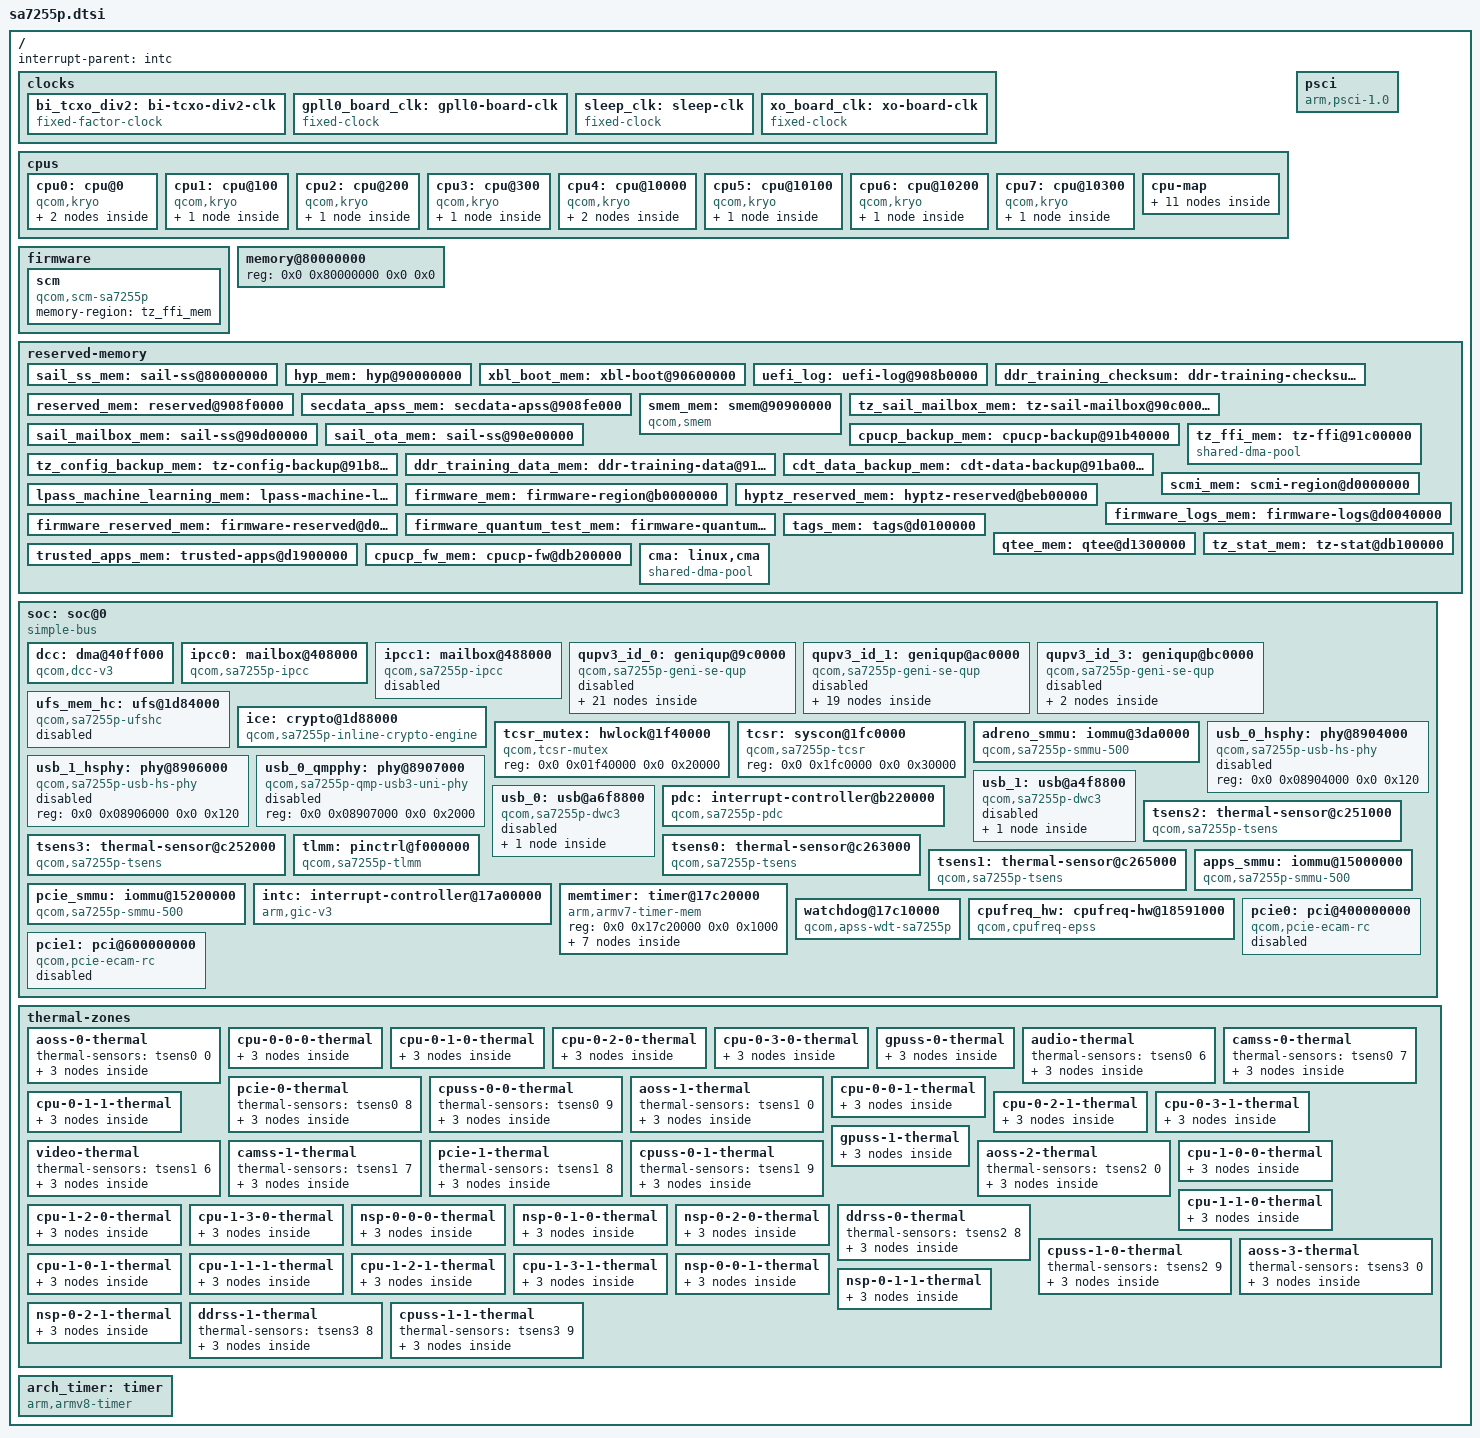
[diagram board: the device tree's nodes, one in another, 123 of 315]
// SPDX-License-Identifier: BSD-3-Clause
/*
 * Copyright (c) 2024 Qualcomm Innovation Center, Inc. All rights reserved.
 */

#include <dt-bindings/interrupt-controller/arm-gic.h>
#include <dt-bindings/mailbox/qcom-ipcc.h>

/ {
	interrupt-parent = <&intc>;

	#address-cells = <2>;
	#size-cells = <2>;

	clocks {
		bi_tcxo_div2: bi-tcxo-div2-clk {
			compatible = "fixed-factor-clock";
			clocks = <&xo_board_clk>;
			clock-mult = <1>;
			clock-div = <2>;
			#clock-cells = <0>;
		};

		gpll0_board_clk: gpll0-board-clk {
			compatible = "fixed-clock";
			#clock-cells = <0>;
		};

		sleep_clk: sleep-clk {
			compatible = "fixed-clock";
			#clock-cells = <0>;
		};

		xo_board_clk: xo-board-clk {
			compatible = "fixed-clock";
			#clock-cells = <0>;
		};
	};

	cpus {
		#address-cells = <2>;
		#size-cells = <0>;

		cpu0: cpu@0 {
			device_type = "cpu";
			compatible = "qcom,kryo";
			reg = <0x0 0x0>;
			enable-method = "psci";
			qcom,freq-domain = <&cpufreq_hw 0>;
			next-level-cache = <&L2_0>;
			L2_0: l2-cache {
			      compatible = "cache";
			      cache-level = <2>;
			      next-level-cache = <&L3_0>;

				L3_0: l3-cache {
				      compatible = "cache";
				      cache-level = <3>;
				};
			};
		};

		cpu1: cpu@100 {
			device_type = "cpu";
			compatible = "qcom,kryo";
			reg = <0x0 0x100>;
			enable-method = "psci";
			qcom,freq-domain = <&cpufreq_hw 0>;
			next-level-cache = <&L2_1>;
			L2_1: l2-cache {
			      compatible = "cache";
			      cache-level = <2>;
			      next-level-cache = <&L3_0>;
			};
		};

		cpu2: cpu@200 {
			device_type = "cpu";
			compatible = "qcom,kryo";
			reg = <0x0 0x200>;
			enable-method = "psci";
			qcom,freq-domain = <&cpufreq_hw 1>;
			next-level-cache = <&L2_2>;
			L2_2: l2-cache {
			      compatible = "cache";
			      cache-level = <2>;
			      next-level-cache = <&L3_0>;
			};
		};

		cpu3: cpu@300 {
			device_type = "cpu";
			compatible = "qcom,kryo";
			reg = <0x0 0x300>;
			enable-method = "psci";
			qcom,freq-domain = <&cpufreq_hw 1>;
			next-level-cache = <&L2_3>;
			L2_3: l2-cache {
			      compatible = "cache";
			      cache-level = <2>;
			      next-level-cache = <&L3_0>;
			};
		};

		cpu4: cpu@10000 {
			device_type = "cpu";
			compatible = "qcom,kryo";
			reg = <0x0 0x10000>;
			enable-method = "psci";
			qcom,freq-domain = <&cpufreq_hw 2>;
			next-level-cache = <&L2_4>;
			L2_4: l2-cache {
			      compatible = "cache";
			      cache-level = <2>;
			      next-level-cache = <&L3_1>;
				L3_1: l3-cache {
				      compatible = "cache";
				      cache-level = <3>;
				};
			};
		};

		cpu5: cpu@10100 {
			device_type = "cpu";
			compatible = "qcom,kryo";
			reg = <0x0 0x10100>;
			enable-method = "psci";
			qcom,freq-domain = <&cpufreq_hw 2>;
			next-level-cache = <&L2_5>;
			L2_5: l2-cache {
			      compatible = "cache";
			      cache-level = <2>;
			      next-level-cache = <&L3_1>;
			};
		};

		cpu6: cpu@10200 {
			device_type = "cpu";
			compatible = "qcom,kryo";
			reg = <0x0 0x10200>;
			enable-method = "psci";
			qcom,freq-domain = <&cpufreq_hw 2>;
			next-level-cache = <&L2_6>;
			L2_6: l2-cache {
			      compatible = "cache";
			      cache-level = <2>;
			      next-level-cache = <&L3_1>;
			};
		};

		cpu7: cpu@10300 {
			device_type = "cpu";
			compatible = "qcom,kryo";
			reg = <0x0 0x10300>;
			enable-method = "psci";
			qcom,freq-domain = <&cpufreq_hw 2>;
			next-level-cache = <&L2_7>;
			L2_7: l2-cache {
			      compatible = "cache";
			      cache-level = <2>;
			      next-level-cache = <&L3_1>;
			};
		};

		cpu-map {
			cluster0 {
				core0 {
					cpu = <&cpu0>;
				};

				core1 {
					cpu = <&cpu1>;
				};
			};

			cluster1 {
				core0 {
					cpu = <&cpu2>;
				};

				core1 {
					cpu = <&cpu3>;
				};
			};

			cluster2 {
				core0 {
					cpu = <&cpu4>;
				};

				core1 {
					cpu = <&cpu5>;
				};

				core2 {
					cpu = <&cpu6>;
				};

				core3 {
					cpu = <&cpu7>;
				};
			};
		};
	};

	firmware: firmware {
		scm {
			compatible = "qcom,scm-sa7255p", "qcom,scm";
			memory-region = <&tz_ffi_mem>;
		};
	};

	memory@80000000 {
		device_type = "memory";
		reg = <0x0 0x80000000 0x0 0x0>;
	};

	psci {
		compatible = "arm,psci-1.0";
		method = "smc";
		mode-bootloader = <0x10001 0x2>;
		mode-edl = <0 0x1>;
	};

	reserved-memory {
		#address-cells = <2>;
		#size-cells = <2>;
		ranges;

		sail_ss_mem: sail-ss@80000000 {
			reg = <0x0 0x80000000 0x0 0x10000000>;
			no-map;
		};

		hyp_mem: hyp@90000000 {
			reg = <0x0 0x90000000 0x0 0x600000>;
			no-map;
		};

		xbl_boot_mem: xbl-boot@90600000 {
			reg = <0x0 0x90600000 0x0 0x200000>;
			no-map;
		};

		uefi_log: uefi-log@908b0000 {
			reg = <0x0 0x908b0000 0x0 0x10000>;
			no-map;
		};

		ddr_training_checksum: ddr-training-checksum@908c0000 {
			reg = <0x0 0x908c0000 0x0 0x1000>;
			no-map;
		};

		reserved_mem: reserved@908f0000 {
			reg = <0x0 0x908f0000 0x0 0xe000>;
			no-map;
		};

		secdata_apss_mem: secdata-apss@908fe000 {
			reg = <0x0 0x908fe000 0x0 0x2000>;
			no-map;
		};

		smem_mem: smem@90900000 {
			compatible = "qcom,smem";
			reg = <0x0 0x90900000 0x0 0x200000>;
			no-map;
			hwlocks = <&tcsr_mutex 3>;
		};

		tz_sail_mailbox_mem: tz-sail-mailbox@90c00000 {
			reg = <0x0 0x90c00000 0x0 0x100000>;
			no-map;
		};

		sail_mailbox_mem: sail-ss@90d00000 {
			reg = <0x0 0x90d00000 0x0 0x100000>;
			no-map;
		};

		sail_ota_mem: sail-ss@90e00000 {
			reg = <0x0 0x90e00000 0x0 0x300000>;
			no-map;
		};

		cpucp_backup_mem: cpucp-backup@91b40000 {
			reg = <0x0 0x91b40000 0x0 0x40000>;
			no-map;
		};

		tz_config_backup_mem: tz-config-backup@91b80000 {
			reg = <0x0 0x91b80000 0x0 0x10000>;
			no-map;
		};

		ddr_training_data_mem: ddr-training-data@91b90000 {
			reg = <0x0 0x91b90000 0x0 0x10000>;
			no-map;
		};

		cdt_data_backup_mem: cdt-data-backup@91ba0000 {
			reg = <0x0 0x91ba0000 0x0 0x1000>;
			no-map;
		};

		tz_ffi_mem: tz-ffi@91c00000 {
			compatible = "shared-dma-pool";
			reg = <0x0 0x91c00000 0x0 0x1400000>;
			no-map;
		};

		lpass_machine_learning_mem: lpass-machine-learning@93b00000 {
			reg = <0x0 0x93b00000 0x0 0xf00000>;
			no-map;
		};

		firmware_mem: firmware-region@b0000000 {
			reg = <0x0 0xb0000000 0x0 0x800000>;
			no-map;
		};

		hyptz_reserved_mem: hyptz-reserved@beb00000 {
			reg = <0x0 0xbeb00000 0x0 0x11500000>;
			no-map;
		};

		scmi_mem: scmi-region@d0000000 {
			reg = <0x0 0xd0000000 0x0 0x40000>;
			no-map;
		};

		firmware_logs_mem: firmware-logs@d0040000 {
			reg = <0x0 0xd0040000 0x0 0x10000>;
			no-map;
		};

		firmware_reserved_mem: firmware-reserved@d0054000 {
			reg = <0x0 0xd0054000 0x0 0x9c000>;
			no-map;
		};

		firmware_quantum_test_mem: firmware-quantum-test@d00f0000 {
			reg = <0x0 0xd00f0000 0x0 0x10000>;
			no-map;
		};

		tags_mem: tags@d0100000 {
			reg = <0x0 0xd0100000 0x0 0x1200000>;
			no-map;
		};

		qtee_mem: qtee@d1300000 {
			reg = <0x0 0xd1300000 0x0 0x500000>;
			no-map;
		};

		trusted_apps_mem: trusted-apps@d1900000 {
			reg = <0x0 0xd1900000 0x0 0x3800000>;
			no-map;
		};

		tz_stat_mem: tz-stat@db100000 {
			reg = <0x0 0xdb100000 0x0 0x100000>;
			no-map;
		};

		cpucp_fw_mem: cpucp-fw@db200000 {
			reg = <0x0 0xdb200000 0x0 0x100000>;
			no-map;
		};

		cma: linux,cma {
			compatible = "shared-dma-pool";
			alloc-ranges = <0x0 0x00000000 0x0 0xdfffffff>;
			reusable;
			alignment = <0x0 0x400000>;
			size = <0x0 0x2000000>;
			linux,cma-default;
		};
	};

	soc: soc@0 {
		compatible = "simple-bus";
		#address-cells = <2>;
		#size-cells = <2>;
		ranges = <0 0 0 0 0x10 0>;

		dcc: dma@40ff000 {
			compatible = "qcom,dcc-v3", "qcom,dcc";
			reg = <0x0 0x040ff000 0x0 0x1000>,
			      <0x0 0x040b8800 0x0 0x6000>;
			qcom,dcc-offset = <0x38800>;
		};

		ipcc0: mailbox@408000 {
			compatible = "qcom,sa7255p-ipcc", "qcom,ipcc";
			reg = <0x0 0x408000 0x0 0x1000>;
			interrupts = <GIC_SPI 229 IRQ_TYPE_LEVEL_HIGH>;
			interrupt-controller;
			#interrupt-cells = <3>;
			#mbox-cells = <2>;
		};

		ipcc1: mailbox@488000 {
			compatible = "qcom,sa7255p-ipcc", "qcom,ipcc";
			reg = <0x0 0x488000 0x0 0x1000>;
			interrupts = <GIC_SPI 231 IRQ_TYPE_LEVEL_HIGH>;
			interrupt-controller;
			#interrupt-cells = <3>;
			#mbox-cells = <2>;
			status = "disabled";
		};

		qupv3_id_0: geniqup@9c0000 {
			compatible = "qcom,sa7255p-geni-se-qup";
			reg = <0x0 0x9c0000 0x0 0x2000>;
			#address-cells = <2>;
			#size-cells = <2>;
			ranges;
			iommus = <&apps_smmu 0x403 0x0>;
			status = "disabled";

			i2c0: i2c@980000 {
				compatible = "qcom,sa7255p-geni-i2c";
				reg = <0x0 0x980000 0x0 0x4000>;
				#address-cells = <1>;
				#size-cells = <0>;
				interrupts = <GIC_SPI 550 IRQ_TYPE_LEVEL_HIGH>;
				status = "disabled";
			};

			spi0: spi@980000 {
				compatible = "qcom,sa7255p-geni-spi";
				reg = <0x0 0x980000 0x0 0x4000>;
				#address-cells = <1>;
				#size-cells = <0>;
				interrupts = <GIC_SPI 550 IRQ_TYPE_LEVEL_HIGH>;
				status = "disabled";
			};

			uart0: serial@980000 {
				compatible = "qcom,sa7255p-geni-uart";
				reg = <0x0 0x980000 0x0 0x4000>;
				interrupts = <GIC_SPI 550 IRQ_TYPE_LEVEL_HIGH>;
				status = "disabled";
			};

			i2c1: i2c@984000 {
				compatible = "qcom,sa7255p-geni-i2c";
				reg = <0x0 0x984000 0x0 0x4000>;
				#address-cells = <1>;
				#size-cells = <0>;
				interrupts = <GIC_SPI 551 IRQ_TYPE_LEVEL_HIGH>;
				status = "disabled";
			};

			spi1: spi@984000 {
				compatible = "qcom,sa7255p-geni-spi";
				reg = <0x0 0x984000 0x0 0x4000>;
				#address-cells = <1>;
				#size-cells = <0>;
				interrupts = <GIC_SPI 551 IRQ_TYPE_LEVEL_HIGH>;
				status = "disabled";
			};

			uart1: serial@984000 {
				compatible = "qcom,sa7255p-geni-uart";
				reg = <0x0 0x984000 0x0 0x4000>;
				interrupts = <GIC_SPI 551 IRQ_TYPE_LEVEL_HIGH>;
				status = "disabled";
			};

			i2c2: i2c@988000 {
				compatible = "qcom,sa7255p-geni-i2c";
				reg = <0x0 0x988000 0x0 0x4000>;
				#address-cells = <1>;
				#size-cells = <0>;
				interrupts = <GIC_SPI 529 IRQ_TYPE_LEVEL_HIGH>;
				status = "disabled";
			};

			spi2: spi@988000 {
				compatible = "qcom,sa7255p-geni-spi";
				reg = <0x0 0x988000 0x0 0x4000>;
				#address-cells = <1>;
				#size-cells = <0>;
				interrupts = <GIC_SPI 529 IRQ_TYPE_LEVEL_HIGH>;
				status = "disabled";
			};

			uart2: serial@988000 {
				compatible = "qcom,sa7255p-geni-uart";
				reg = <0x0 0x988000 0x0 0x4000>;
				interrupts = <GIC_SPI 529 IRQ_TYPE_LEVEL_HIGH>;
				status = "disabled";
			};

			i2c3: i2c@98c000 {
				compatible = "qcom,sa7255p-geni-i2c";
				reg = <0x0 0x98c000 0x0 0x4000>;
				#address-cells = <1>;
				#size-cells = <0>;
				interrupts = <GIC_SPI 530 IRQ_TYPE_LEVEL_HIGH>;
				status = "disabled";
			};

			spi3: spi@98c000 {
				compatible = "qcom,sa7255p-geni-spi";
				reg = <0x0 0x98c000 0x0 0x4000>;
				#address-cells = <1>;
				#size-cells = <0>;
				interrupts = <GIC_SPI 530 IRQ_TYPE_LEVEL_HIGH>;
				status = "disabled";
			};

			uart3: serial@98c000 {
				compatible = "qcom,sa7255p-geni-uart";
				reg = <0x0 0x98c000 0x0 0x4000>;
				interrupts = <GIC_SPI 530 IRQ_TYPE_LEVEL_HIGH>;
				status = "disabled";
			};

			i2c4: i2c@990000 {
				compatible = "qcom,sa7255p-geni-i2c";
				reg = <0x0 0x990000 0x0 0x4000>;
				#address-cells = <1>;
				#size-cells = <0>;
				interrupts = <GIC_SPI 531 IRQ_TYPE_LEVEL_HIGH>;
				status = "disabled";
			};

			spi4: spi@990000 {
				compatible = "qcom,sa7255p-geni-spi";
				reg = <0x0 0x990000 0x0 0x4000>;
				#address-cells = <1>;
				#size-cells = <0>;
				interrupts = <GIC_SPI 531 IRQ_TYPE_LEVEL_HIGH>;
				status = "disabled";
			};

			uart4: serial@990000 {
				compatible = "qcom,sa7255p-geni-uart";
				reg = <0x0 0x990000 0x0 0x4000>;
				interrupts = <GIC_SPI 531 IRQ_TYPE_LEVEL_HIGH>;
				status = "disabled";
			};

			i2c5: i2c@994000 {
				compatible = "qcom,sa7255p-geni-i2c";
				reg = <0x0 0x994000 0x0 0x4000>;
				#address-cells = <1>;
				#size-cells = <0>;
				interrupts = <GIC_SPI 535 IRQ_TYPE_LEVEL_HIGH>;
				status = "disabled";
			};

			spi5: spi@994000 {
				compatible = "qcom,sa7255p-geni-spi";
				reg = <0x0 0x994000 0x0 0x4000>;
				#address-cells = <1>;
				#size-cells = <0>;
				interrupts = <GIC_SPI 535 IRQ_TYPE_LEVEL_HIGH>;
				status = "disabled";
			};

			uart5: serial@994000 {
				compatible = "qcom,sa7255p-geni-uart";
				reg = <0x0 0x994000 0x0 0x4000>;
				interrupts = <GIC_SPI 535 IRQ_TYPE_LEVEL_HIGH>;
				status = "disabled";
			};

			i2c6: i2c@998000 {
				compatible = "qcom,sa7255p-geni-i2c";
				reg = <0x0 0x998000 0x0 0x4000>;
				#address-cells = <1>;
				#size-cells = <0>;
				interrupts = <GIC_SPI 536 IRQ_TYPE_LEVEL_HIGH>;
				status = "disabled";
			};

			spi6: spi@998000 {
				compatible = "qcom,sa7255p-geni-spi";
				reg = <0x0 0x998000 0x0 0x4000>;
				#address-cells = <1>;
				#size-cells = <0>;
				interrupts = <GIC_SPI 536 IRQ_TYPE_LEVEL_HIGH>;
				status = "disabled";
			};

			uart7: serial@99c000 {
				compatible = "qcom,sa7255p-geni-debug-uart";
				reg = <0x0 0x0099c000 0x0 0x4000>;
				interrupts = <GIC_SPI 126 IRQ_TYPE_LEVEL_HIGH>;
				status = "disabled";
			};

		};

		qupv3_id_1: geniqup@ac0000 {
			compatible = "qcom,sa7255p-geni-se-qup";
			reg = <0x0 0x00ac0000 0x0 0x2000>;
			#address-cells = <2>;
			#size-cells = <2>;
			ranges;
			iommus = <&apps_smmu 0x443 0x0>;
			status = "disabled";

			i2c8: i2c@a80000 {
				compatible = "qcom,sa7255p-geni-i2c";
				reg = <0x0 0xa80000 0x0 0x4000>;
				#address-cells = <1>;
				#size-cells = <0>;
				interrupts = <GIC_SPI 353 IRQ_TYPE_LEVEL_HIGH>;
				status = "disabled";
			};

			spi8: spi@a80000 {
				compatible = "qcom,sa7255p-geni-spi";
				reg = <0x0 0xa80000 0x0 0x4000>;
				#address-cells = <1>;
				#size-cells = <0>;
				interrupts = <GIC_SPI 353 IRQ_TYPE_LEVEL_HIGH>;
				status = "disabled";
			};

			i2c9: i2c@a84000 {
				compatible = "qcom,sa7255p-geni-i2c";
				reg = <0x0 0xa84000 0x0 0x4000>;
				#address-cells = <1>;
				#size-cells = <0>;
				interrupts = <GIC_SPI 354 IRQ_TYPE_LEVEL_HIGH>;
				status = "disabled";
			};

			spi9: spi@a84000 {
				compatible = "qcom,sa7255p-geni-spi";
				reg = <0x0 0xa84000 0x0 0x4000>;
				#address-cells = <1>;
				#size-cells = <0>;
				interrupts = <GIC_SPI 354 IRQ_TYPE_LEVEL_HIGH>;
				status = "disabled";
			};

			uart9: serial@a84000 {
				compatible = "qcom,sa7255p-geni-uart";
				reg = <0x0 0x00a84000 0x0 0x4000>;
				interrupts = <GIC_SPI 354 IRQ_TYPE_LEVEL_HIGH>;
				status = "disabled";
			};

			i2c10: i2c@a88000 {
				compatible = "qcom,sa7255p-geni-i2c";
				reg = <0x0 0xa88000 0x0 0x4000>;
				#address-cells = <1>;
				#size-cells = <0>;
				interrupts = <GIC_SPI 355 IRQ_TYPE_LEVEL_HIGH>;
				status = "disabled";
			};

			spi10: spi@a88000 {
				compatible = "qcom,sa7255p-geni-spi";
				reg = <0x0 0xa88000 0x0 0x4000>;
				#address-cells = <1>;
				#size-cells = <0>;
				interrupts = <GIC_SPI 355 IRQ_TYPE_LEVEL_HIGH>;
				status = "disabled";
			};

			uart10: serial@a88000 {
				compatible = "qcom,sa7255p-geni-uart";
				reg = <0x0 0xa88000 0x0 0x4000>;
				interrupts = <GIC_SPI 355 IRQ_TYPE_LEVEL_HIGH>;
				status = "disabled";
			};

			i2c11: i2c@a8c000 {
				compatible = "qcom,sa7255p-geni-i2c";
				reg = <0x0 0xa8c000 0x0 0x4000>;
				#address-cells = <1>;
				#size-cells = <0>;
				interrupts = <GIC_SPI 356 IRQ_TYPE_LEVEL_HIGH>;
				status = "disabled";
			};

			spi11: spi@a8c000 {
				compatible = "qcom,sa7255p-geni-spi";
				reg = <0x0 0xa8c000 0x0 0x4000>;
				#address-cells = <1>;
				#size-cells = <0>;
				interrupts = <GIC_SPI 356 IRQ_TYPE_LEVEL_HIGH>;
				status = "disabled";
			};

			uart11: serial@a8c000 {
				compatible = "qcom,sa7255p-geni-debug-uart";
				reg = <0x0 0x00a8c000 0x0 0x4000>;
				interrupts = <GIC_SPI 356 IRQ_TYPE_LEVEL_HIGH>;
				status = "disabled";
			};

			i2c12: i2c@a90000 {
				compatible = "qcom,sa7255p-geni-i2c";
				reg = <0x0 0xa90000 0x0 0x4000>;
				#address-cells = <1>;
				#size-cells = <0>;
				interrupts = <GIC_SPI 357 IRQ_TYPE_LEVEL_HIGH>;
				status = "disabled";
			};

			spi12: spi@a90000 {
				compatible = "qcom,sa7255p-geni-spi";
				reg = <0x0 0xa90000 0x0 0x4000>;
				#address-cells = <1>;
				#size-cells = <0>;
				interrupts = <GIC_SPI 357 IRQ_TYPE_LEVEL_HIGH>;
				status = "disabled";
			};

			uart12: serial@a90000 {
				compatible = "qcom,sa7255p-geni-uart";
				reg = <0x0 0x00a90000 0x0 0x4000>;
				interrupts = <GIC_SPI 357 IRQ_TYPE_LEVEL_HIGH>;
				status = "disabled";
			};

			i2c13: i2c@a94000 {
				compatible = "qcom,sa7255p-geni-i2c";
				reg = <0x0 0xa94000 0x0 0x4000>;
				#address-cells = <1>;
				#size-cells = <0>;
				interrupts = <GIC_SPI 358 IRQ_TYPE_LEVEL_HIGH>;
				status = "disabled";
			};

			spi13: spi@a94000 {
				compatible = "qcom,sa7255p-geni-spi";
				reg = <0x0 0xa94000 0x0 0x4000>;
				#address-cells = <1>;
				#size-cells = <0>;
				interrupts = <GIC_SPI 358 IRQ_TYPE_LEVEL_HIGH>;
				status = "disabled";
			};

			uart13: serial@a94000 {
				compatible = "qcom,sa7255p-geni-uart";
				reg = <0x0 0x00a94000 0x0 0x4000>;
				interrupts = <GIC_SPI 358 IRQ_TYPE_LEVEL_HIGH>;
				status = "disabled";
			};

			i2c14: i2c@a98000 {
				compatible = "qcom,sa7255p-geni-i2c";
				reg = <0x0 0xa98000 0x0 0x4000>;
				#address-cells = <1>;
				#size-cells = <0>;
				interrupts = <GIC_SPI 835 IRQ_TYPE_LEVEL_HIGH>;
				status = "disabled";
			};

			i2c15: i2c@a9c000 {
				compatible = "qcom,sa7255p-geni-i2c";
				reg = <0x0 0xa9c000 0x0 0x4000>;
				#address-cells = <1>;
				#size-cells = <0>;
				interrupts = <GIC_SPI 125 IRQ_TYPE_LEVEL_HIGH>;
				status = "disabled";
			};
		};

		qupv3_id_3: geniqup@bc0000 {
			compatible = "qcom,sa7255p-geni-se-qup";
			reg = <0x0 0xbc0000 0x0 0x2000>;
			#address-cells = <2>;
			#size-cells = <2>;
			ranges;
			iommus = <&apps_smmu 0x43 0x0>;
			status = "disabled";

			i2c16: i2c@b80000 {
				compatible = "qcom,sa7255p-geni-i2c";
				reg = <0x0 0xb80000 0x0 0x4000>;
				#address-cells = <1>;
				#size-cells = <0>;
				interrupts = <GIC_SPI 830 IRQ_TYPE_LEVEL_HIGH>;
				status = "disabled";
			};

			spi16: spi@b80000 {
				compatible = "qcom,sa7255p-geni-spi";
				reg = <0x0 0xb80000 0x0 0x4000>;
				#address-cells = <1>;
				#size-cells = <0>;
				interrupts = <GIC_SPI 830 IRQ_TYPE_LEVEL_HIGH>;
				status = "disabled";
			};
		};

		ufs_mem_hc: ufs@1d84000 {
			compatible = "qcom,sa7255p-ufshc", "qcom,ufshc", "jedec,ufs-2.0";
			reg = <0x0 0x01d84000 0x0 0x3000>;
			interrupts = <GIC_SPI 265 IRQ_TYPE_LEVEL_HIGH>;
			lanes-per-direction = <2>;
			iommus = <&apps_smmu 0x100 0x0>;
			dma-coherent;
			qcom,ice = <&ice>;
			status = "disabled";
		};

		ice: crypto@1d88000 {
			compatible = "qcom,sa7255p-inline-crypto-engine",
				     "qcom,inline-crypto-engine";
			reg = <0x0 0x01d88000 0x0 0x10000>;
			qcom,ice-use-hwkm;
			qcom,ice-skip-clk;
		};

		tcsr_mutex: hwlock@1f40000 {
			compatible = "qcom,tcsr-mutex";
			reg = <0x0 0x01f40000 0x0 0x20000>;
			#hwlock-cells = <1>;
		};

		tcsr: syscon@1fc0000 {
			compatible = "qcom,sa7255p-tcsr", "syscon";
			reg = <0x0 0x1fc0000 0x0 0x30000>;
		};

		adreno_smmu: iommu@3da0000 {
			compatible = "qcom,sa7255p-smmu-500", "qcom,adreno-smmu",
				     "qcom,smmu-500", "arm,mmu-500";
			reg = <0x0 0x03da0000 0x0 0x20000>;
			#iommu-cells = <2>;
			#global-interrupts = <2>;
			dma-coherent;

			interrupts = <GIC_SPI 672 IRQ_TYPE_LEVEL_HIGH>,
				     <GIC_SPI 673 IRQ_TYPE_LEVEL_HIGH>,
				     <GIC_SPI 678 IRQ_TYPE_LEVEL_HIGH>,
				     <GIC_SPI 679 IRQ_TYPE_LEVEL_HIGH>,
				     <GIC_SPI 680 IRQ_TYPE_LEVEL_HIGH>,
				     <GIC_SPI 681 IRQ_TYPE_LEVEL_HIGH>,
				     <GIC_SPI 682 IRQ_TYPE_LEVEL_HIGH>,
				     <GIC_SPI 683 IRQ_TYPE_LEVEL_HIGH>,
				     <GIC_SPI 684 IRQ_TYPE_LEVEL_HIGH>,
				     <GIC_SPI 685 IRQ_TYPE_LEVEL_HIGH>,
				     <GIC_SPI 686 IRQ_TYPE_LEVEL_HIGH>,
				     <GIC_SPI 687 IRQ_TYPE_LEVEL_HIGH>;
		};

		usb_0_hsphy: phy@8904000 {
			compatible = "qcom,sa7255p-usb-hs-phy",
				     "qcom,usb-snps-hs-5nm-phy";
			reg = <0x0 0x08904000 0x0 0x120>;
			#phy-cells = <0>;

			status = "disabled";
		};

		usb_1_hsphy: phy@8906000 {
			compatible = "qcom,sa7255p-usb-hs-phy",
				     "qcom,usb-snps-hs-5nm-phy";
			reg = <0x0 0x08906000 0x0 0x120>;
			#phy-cells = <0>;

			status = "disabled";
		};

		usb_0_qmpphy: phy@8907000 {
			compatible = "qcom,sa7255p-qmp-usb3-uni-phy";
			reg = <0x0 0x08907000 0x0 0x2000>;

			#phy-cells = <0>;

			status = "disabled";
		};

		usb_1: usb@a4f8800 {
			compatible = "qcom,sa7255p-dwc3", "qcom,dwc3";
			reg = <0x0 0x0a4f8800 0x0 0x400>;
			#address-cells = <2>;
			#size-cells = <2>;
			ranges;

			interrupts-extended = <&intc GIC_SPI 444 IRQ_TYPE_LEVEL_HIGH>,
					      <&pdc 10 IRQ_TYPE_EDGE_BOTH>,
					      <&pdc 9 IRQ_TYPE_EDGE_BOTH>;
			interrupt-names = "pwr_event",
					  "dp_hs_phy_irq",
					  "dm_hs_phy_irq";

			status = "disabled";

			usb_1_dwc3: usb@a400000 {
				compatible = "snps,dwc3";
				reg = <0x0 0x0a400000 0x0 0xe000>;
				interrupts = <GIC_SPI 442 IRQ_TYPE_LEVEL_HIGH>;
				iommus = <&apps_smmu 0x020 0x0>;
				phys = <&usb_1_hsphy>;
				phy-names = "usb2-phy";
			};
		};

		usb_0: usb@a6f8800 {
			compatible = "qcom,sa7255p-dwc3", "qcom,dwc3";
			reg = <0x0 0x0a6f8800 0x0 0x400>;
			#address-cells = <2>;
			#size-cells = <2>;
			ranges;

			interrupts-extended = <&intc GIC_SPI 287 IRQ_TYPE_LEVEL_HIGH>,
					      <&pdc 14 IRQ_TYPE_EDGE_BOTH>,
					      <&pdc 15 IRQ_TYPE_EDGE_BOTH>,
					      <&pdc 12 IRQ_TYPE_LEVEL_HIGH>;
			interrupt-names = "pwr_event",
					  "dp_hs_phy_irq",
					  "dm_hs_phy_irq",
					  "ss_phy_irq";

			status = "disabled";

			usb_0_dwc3: usb@a600000 {
				compatible = "snps,dwc3";
				reg = <0x0 0x0a600000 0x0 0xe000>;
				interrupts = <GIC_SPI 292 IRQ_TYPE_LEVEL_HIGH>;
				iommus = <&apps_smmu 0x080 0x0>;
				phys = <&usb_0_hsphy>, <&usb_0_qmpphy>;
				phy-names = "usb2-phy", "usb3-phy";
			};
		};

		pdc: interrupt-controller@b220000 {
			compatible = "qcom,sa7255p-pdc", "qcom,pdc";
			reg = <0x0 0x0b220000 0x0 0x30000>,
			      <0x0 0x17c000f0 0x0 0x64>;
			qcom,pdc-ranges = <0 480 40>,
					  <40 140 14>,
					  <54 263 1>,
					  <55 306 4>,
					  <59 312 3>,
					  <62 374 2>,
					  <64 434 2>,
					  <66 438 2>,
					  <70 520 1>,
					  <73 523 1>,
					  <118 568 6>,
					  <124 609 3>,
					  <159 638 1>,
					  <160 720 3>,
					  <169 728 30>,
					  <199 416 2>,
					  <201 449 1>,
					  <202 89 1>,
					  <203 451 1>,
					  <204 462 1>,
					  <205 264 1>,
					  <206 579 1>,
					  <207 653 1>,
					  <208 656 1>,
					  <209 659 1>,
					  <210 122 1>,
					  <211 699 1>,
					  <212 705 1>,
					  <213 450 1>,
					  <214 643 2>,
					  <216 646 5>,
					  <221 390 5>,
					  <226 700 2>,
					  <228 440 1>,
					  <229 663 1>,
					  <230 524 2>,
					  <232 612 3>,
					  <235 723 5>;
			#interrupt-cells = <2>;
			interrupt-parent = <&intc>;
			interrupt-controller;
		};

		tsens2: thermal-sensor@c251000 {
			compatible = "qcom,sa7255p-tsens", "qcom,tsens-v2";
			reg = <0x0 0x0c251000 0x0 0x1ff>,
			      <0x0 0x0c224000 0x0 0x8>;
			interrupts = <GIC_SPI 572 IRQ_TYPE_LEVEL_HIGH>,
				     <GIC_SPI 609 IRQ_TYPE_LEVEL_HIGH>;
			#qcom,sensors = <10>;
			interrupt-names = "uplow", "critical";
			#thermal-sensor-cells = <1>;
		};

		tsens3: thermal-sensor@c252000 {
			compatible = "qcom,sa7255p-tsens", "qcom,tsens-v2";
			reg = <0x0 0x0c252000 0x0 0x1ff>,
			      <0x0 0x0c225000 0x0 0x8>;
			interrupts = <GIC_SPI 573 IRQ_TYPE_LEVEL_HIGH>,
				     <GIC_SPI 610 IRQ_TYPE_LEVEL_HIGH>;
			#qcom,sensors = <10>;
			interrupt-names = "uplow", "critical";
			#thermal-sensor-cells = <1>;
		};

		tsens0: thermal-sensor@c263000 {
			compatible = "qcom,sa7255p-tsens", "qcom,tsens-v2";
			reg = <0x0 0x0c263000 0x0 0x1ff>,
			      <0x0 0x0c222000 0x0 0x8>;
			interrupts = <GIC_SPI 506 IRQ_TYPE_LEVEL_HIGH>,
				     <GIC_SPI 508 IRQ_TYPE_LEVEL_HIGH>;
			#qcom,sensors = <10>;
			interrupt-names = "uplow", "critical";
			#thermal-sensor-cells = <1>;
		};

		tsens1: thermal-sensor@c265000 {
			compatible = "qcom,sa7255p-tsens", "qcom,tsens-v2";
			reg = <0x0 0x0c265000 0x0 0x1ff>,
			      <0x0 0x0c223000 0x0 0x8>;
			interrupts = <GIC_SPI 507 IRQ_TYPE_LEVEL_HIGH>,
				     <GIC_SPI 509 IRQ_TYPE_LEVEL_HIGH>;
			#qcom,sensors = <10>;
			interrupt-names = "uplow", "critical";
			#thermal-sensor-cells = <1>;
		};

		tlmm: pinctrl@f000000 {
			compatible = "qcom,sa7255p-tlmm";
			reg = <0x0 0x0f000000 0x0 0x1000000>;
			interrupts = <GIC_SPI 208 IRQ_TYPE_LEVEL_HIGH>;
			gpio-controller;
			#gpio-cells = <2>;
			interrupt-controller;
			#interrupt-cells = <2>;
			gpio-ranges = <&tlmm 0 0 133>;
			wakeup-parent = <&pdc>;
		};

		apps_smmu: iommu@15000000 {
			compatible = "qcom,sa7255p-smmu-500", "qcom,smmu-500", "arm,mmu-500";
			reg = <0x0 0x15000000 0x0 0x100000>;
			#iommu-cells = <2>;
			#global-interrupts = <2>;

			interrupts = <GIC_SPI 119 IRQ_TYPE_LEVEL_HIGH>,
				     <GIC_SPI 120 IRQ_TYPE_LEVEL_HIGH>,
				     <GIC_SPI  98 IRQ_TYPE_LEVEL_HIGH>,
				     <GIC_SPI  99 IRQ_TYPE_LEVEL_HIGH>,
				     <GIC_SPI 100 IRQ_TYPE_LEVEL_HIGH>,
				     <GIC_SPI 101 IRQ_TYPE_LEVEL_HIGH>,
				     <GIC_SPI 102 IRQ_TYPE_LEVEL_HIGH>,
				     <GIC_SPI 103 IRQ_TYPE_LEVEL_HIGH>,
				     <GIC_SPI 104 IRQ_TYPE_LEVEL_HIGH>,
				     <GIC_SPI 105 IRQ_TYPE_LEVEL_HIGH>,
				     <GIC_SPI 106 IRQ_TYPE_LEVEL_HIGH>,
				     <GIC_SPI 107 IRQ_TYPE_LEVEL_HIGH>,
				     <GIC_SPI 108 IRQ_TYPE_LEVEL_HIGH>,
				     <GIC_SPI 109 IRQ_TYPE_LEVEL_HIGH>,
				     <GIC_SPI 110 IRQ_TYPE_LEVEL_HIGH>,
				     <GIC_SPI 111 IRQ_TYPE_LEVEL_HIGH>,
				     <GIC_SPI 112 IRQ_TYPE_LEVEL_HIGH>,
				     <GIC_SPI 113 IRQ_TYPE_LEVEL_HIGH>,
				     <GIC_SPI 114 IRQ_TYPE_LEVEL_HIGH>,
				     <GIC_SPI 115 IRQ_TYPE_LEVEL_HIGH>,
				     <GIC_SPI 116 IRQ_TYPE_LEVEL_HIGH>,
				     <GIC_SPI 117 IRQ_TYPE_LEVEL_HIGH>,
				     <GIC_SPI 118 IRQ_TYPE_LEVEL_HIGH>,
				     <GIC_SPI 181 IRQ_TYPE_LEVEL_HIGH>,
				     <GIC_SPI 182 IRQ_TYPE_LEVEL_HIGH>,
				     <GIC_SPI 183 IRQ_TYPE_LEVEL_HIGH>,
				     <GIC_SPI 184 IRQ_TYPE_LEVEL_HIGH>,
				     <GIC_SPI 185 IRQ_TYPE_LEVEL_HIGH>,
				     <GIC_SPI 186 IRQ_TYPE_LEVEL_HIGH>,
				     <GIC_SPI 187 IRQ_TYPE_LEVEL_HIGH>,
				     <GIC_SPI 188 IRQ_TYPE_LEVEL_HIGH>,
				     <GIC_SPI 189 IRQ_TYPE_LEVEL_HIGH>,
				     <GIC_SPI 190 IRQ_TYPE_LEVEL_HIGH>,
				     <GIC_SPI 191 IRQ_TYPE_LEVEL_HIGH>,
				     <GIC_SPI 192 IRQ_TYPE_LEVEL_HIGH>,
				     <GIC_SPI 315 IRQ_TYPE_LEVEL_HIGH>,
				     <GIC_SPI 316 IRQ_TYPE_LEVEL_HIGH>,
				     <GIC_SPI 317 IRQ_TYPE_LEVEL_HIGH>,
				     <GIC_SPI 318 IRQ_TYPE_LEVEL_HIGH>,
				     <GIC_SPI 319 IRQ_TYPE_LEVEL_HIGH>,
				     <GIC_SPI 320 IRQ_TYPE_LEVEL_HIGH>,
				     <GIC_SPI 321 IRQ_TYPE_LEVEL_HIGH>,
				     <GIC_SPI 322 IRQ_TYPE_LEVEL_HIGH>,
				     <GIC_SPI 323 IRQ_TYPE_LEVEL_HIGH>,
				     <GIC_SPI 324 IRQ_TYPE_LEVEL_HIGH>,
				     <GIC_SPI 325 IRQ_TYPE_LEVEL_HIGH>,
				     <GIC_SPI 326 IRQ_TYPE_LEVEL_HIGH>,
				     <GIC_SPI 327 IRQ_TYPE_LEVEL_HIGH>,
				     <GIC_SPI 328 IRQ_TYPE_LEVEL_HIGH>,
				     <GIC_SPI 329 IRQ_TYPE_LEVEL_HIGH>,
				     <GIC_SPI 330 IRQ_TYPE_LEVEL_HIGH>,
				     <GIC_SPI 331 IRQ_TYPE_LEVEL_HIGH>,
				     <GIC_SPI 332 IRQ_TYPE_LEVEL_HIGH>,
				     <GIC_SPI 333 IRQ_TYPE_LEVEL_HIGH>,
				     <GIC_SPI 334 IRQ_TYPE_LEVEL_HIGH>,
				     <GIC_SPI 335 IRQ_TYPE_LEVEL_HIGH>,
				     <GIC_SPI 336 IRQ_TYPE_LEVEL_HIGH>,
				     <GIC_SPI 337 IRQ_TYPE_LEVEL_HIGH>,
				     <GIC_SPI 338 IRQ_TYPE_LEVEL_HIGH>,
				     <GIC_SPI 339 IRQ_TYPE_LEVEL_HIGH>,
				     <GIC_SPI 340 IRQ_TYPE_LEVEL_HIGH>,
				     <GIC_SPI 341 IRQ_TYPE_LEVEL_HIGH>,
				     <GIC_SPI 342 IRQ_TYPE_LEVEL_HIGH>,
				     <GIC_SPI 343 IRQ_TYPE_LEVEL_HIGH>,
				     <GIC_SPI 344 IRQ_TYPE_LEVEL_HIGH>,
				     <GIC_SPI 345 IRQ_TYPE_LEVEL_HIGH>,
				     <GIC_SPI 395 IRQ_TYPE_LEVEL_HIGH>,
				     <GIC_SPI 396 IRQ_TYPE_LEVEL_HIGH>,
				     <GIC_SPI 397 IRQ_TYPE_LEVEL_HIGH>,
				     <GIC_SPI 398 IRQ_TYPE_LEVEL_HIGH>,
				     <GIC_SPI 399 IRQ_TYPE_LEVEL_HIGH>,
				     <GIC_SPI 400 IRQ_TYPE_LEVEL_HIGH>,
				     <GIC_SPI 401 IRQ_TYPE_LEVEL_HIGH>,
				     <GIC_SPI 402 IRQ_TYPE_LEVEL_HIGH>,
				     <GIC_SPI 403 IRQ_TYPE_LEVEL_HIGH>,
				     <GIC_SPI 404 IRQ_TYPE_LEVEL_HIGH>,
				     <GIC_SPI 405 IRQ_TYPE_LEVEL_HIGH>,
				     <GIC_SPI 406 IRQ_TYPE_LEVEL_HIGH>,
				     <GIC_SPI 407 IRQ_TYPE_LEVEL_HIGH>,
				     <GIC_SPI 408 IRQ_TYPE_LEVEL_HIGH>,
				     <GIC_SPI 409 IRQ_TYPE_LEVEL_HIGH>,
				     <GIC_SPI 418 IRQ_TYPE_LEVEL_HIGH>,
				     <GIC_SPI 419 IRQ_TYPE_LEVEL_HIGH>,
				     <GIC_SPI 412 IRQ_TYPE_LEVEL_HIGH>,
				     <GIC_SPI 421 IRQ_TYPE_LEVEL_HIGH>,
				     <GIC_SPI 706 IRQ_TYPE_LEVEL_HIGH>,
				     <GIC_SPI 423 IRQ_TYPE_LEVEL_HIGH>,
				     <GIC_SPI 424 IRQ_TYPE_LEVEL_HIGH>,
				     <GIC_SPI 425 IRQ_TYPE_LEVEL_HIGH>,
				     <GIC_SPI 689 IRQ_TYPE_LEVEL_HIGH>,
				     <GIC_SPI 690 IRQ_TYPE_LEVEL_HIGH>,
				     <GIC_SPI 691 IRQ_TYPE_LEVEL_HIGH>,
				     <GIC_SPI 692 IRQ_TYPE_LEVEL_HIGH>,
				     <GIC_SPI 693 IRQ_TYPE_LEVEL_HIGH>,
				     <GIC_SPI 694 IRQ_TYPE_LEVEL_HIGH>,
				     <GIC_SPI 695 IRQ_TYPE_LEVEL_HIGH>,
				     <GIC_SPI 696 IRQ_TYPE_LEVEL_HIGH>,
				     <GIC_SPI 410 IRQ_TYPE_LEVEL_HIGH>,
				     <GIC_SPI 411 IRQ_TYPE_LEVEL_HIGH>,
				     <GIC_SPI 420 IRQ_TYPE_LEVEL_HIGH>,
				     <GIC_SPI 413 IRQ_TYPE_LEVEL_HIGH>,
				     <GIC_SPI 422 IRQ_TYPE_LEVEL_HIGH>,
				     <GIC_SPI 707 IRQ_TYPE_LEVEL_HIGH>,
				     <GIC_SPI 708 IRQ_TYPE_LEVEL_HIGH>,
				     <GIC_SPI 709 IRQ_TYPE_LEVEL_HIGH>,
				     <GIC_SPI 710 IRQ_TYPE_LEVEL_HIGH>,
				     <GIC_SPI 711 IRQ_TYPE_LEVEL_HIGH>,
				     <GIC_SPI 414 IRQ_TYPE_LEVEL_HIGH>,
				     <GIC_SPI 712 IRQ_TYPE_LEVEL_HIGH>,
				     <GIC_SPI 713 IRQ_TYPE_LEVEL_HIGH>,
				     <GIC_SPI 714 IRQ_TYPE_LEVEL_HIGH>,
				     <GIC_SPI 715 IRQ_TYPE_LEVEL_HIGH>,
				     <GIC_SPI 912 IRQ_TYPE_LEVEL_HIGH>,
				     <GIC_SPI 911 IRQ_TYPE_LEVEL_HIGH>,
				     <GIC_SPI 910 IRQ_TYPE_LEVEL_HIGH>,
				     <GIC_SPI 909 IRQ_TYPE_LEVEL_HIGH>,
				     <GIC_SPI 908 IRQ_TYPE_LEVEL_HIGH>,
				     <GIC_SPI 907 IRQ_TYPE_LEVEL_HIGH>,
				     <GIC_SPI 906 IRQ_TYPE_LEVEL_HIGH>,
				     <GIC_SPI 905 IRQ_TYPE_LEVEL_HIGH>,
				     <GIC_SPI 904 IRQ_TYPE_LEVEL_HIGH>,
				     <GIC_SPI 903 IRQ_TYPE_LEVEL_HIGH>,
				     <GIC_SPI 902 IRQ_TYPE_LEVEL_HIGH>,
				     <GIC_SPI 901 IRQ_TYPE_LEVEL_HIGH>,
				     <GIC_SPI 900 IRQ_TYPE_LEVEL_HIGH>,
				     <GIC_SPI 899 IRQ_TYPE_LEVEL_HIGH>,
				     <GIC_SPI 898 IRQ_TYPE_LEVEL_HIGH>,
				     <GIC_SPI 897 IRQ_TYPE_LEVEL_HIGH>,
				     <GIC_SPI 896 IRQ_TYPE_LEVEL_HIGH>,
				     <GIC_SPI 895 IRQ_TYPE_LEVEL_HIGH>;
		};

		pcie_smmu: iommu@15200000 {
			compatible = "qcom,sa7255p-smmu-500", "qcom,smmu-500", "arm,mmu-500";
			reg = <0x0 0x15200000 0x0 0x80000>;
			#iommu-cells = <2>;
			#global-interrupts = <2>;
			dma-coherent;

			interrupts = <GIC_SPI 920 IRQ_TYPE_LEVEL_HIGH>,
				     <GIC_SPI 921 IRQ_TYPE_LEVEL_HIGH>,
				     <GIC_SPI 925 IRQ_TYPE_LEVEL_HIGH>,
				     <GIC_SPI 926 IRQ_TYPE_LEVEL_HIGH>,
				     <GIC_SPI 927 IRQ_TYPE_LEVEL_HIGH>,
				     <GIC_SPI 928 IRQ_TYPE_LEVEL_HIGH>,
				     <GIC_SPI 950 IRQ_TYPE_LEVEL_HIGH>,
				     <GIC_SPI 951 IRQ_TYPE_LEVEL_HIGH>,
				     <GIC_SPI 952 IRQ_TYPE_LEVEL_HIGH>,
				     <GIC_SPI 953 IRQ_TYPE_LEVEL_HIGH>,
				     <GIC_SPI 954 IRQ_TYPE_LEVEL_HIGH>,
				     <GIC_SPI 955 IRQ_TYPE_LEVEL_HIGH>,
				     <GIC_SPI 956 IRQ_TYPE_LEVEL_HIGH>,
				     <GIC_SPI 957 IRQ_TYPE_LEVEL_HIGH>,
				     <GIC_SPI 958 IRQ_TYPE_LEVEL_HIGH>,
				     <GIC_SPI 885 IRQ_TYPE_LEVEL_HIGH>,
				     <GIC_SPI 886 IRQ_TYPE_LEVEL_HIGH>,
				     <GIC_SPI 887 IRQ_TYPE_LEVEL_HIGH>,
				     <GIC_SPI 888 IRQ_TYPE_LEVEL_HIGH>,
				     <GIC_SPI 820 IRQ_TYPE_LEVEL_HIGH>,
				     <GIC_SPI 822 IRQ_TYPE_LEVEL_HIGH>,
				     <GIC_SPI 823 IRQ_TYPE_LEVEL_HIGH>,
				     <GIC_SPI 310 IRQ_TYPE_LEVEL_HIGH>,
				     <GIC_SPI 446 IRQ_TYPE_LEVEL_HIGH>,
				     <GIC_SPI 447 IRQ_TYPE_LEVEL_HIGH>,
				     <GIC_SPI 452 IRQ_TYPE_LEVEL_HIGH>,
				     <GIC_SPI 840 IRQ_TYPE_LEVEL_HIGH>,
				     <GIC_SPI 841 IRQ_TYPE_LEVEL_HIGH>,
				     <GIC_SPI 842 IRQ_TYPE_LEVEL_HIGH>,
				     <GIC_SPI 843 IRQ_TYPE_LEVEL_HIGH>,
				     <GIC_SPI 844 IRQ_TYPE_LEVEL_HIGH>,
				     <GIC_SPI 845 IRQ_TYPE_LEVEL_HIGH>,
				     <GIC_SPI 846 IRQ_TYPE_LEVEL_HIGH>,
				     <GIC_SPI 847 IRQ_TYPE_LEVEL_HIGH>,
				     <GIC_SPI 848 IRQ_TYPE_LEVEL_HIGH>,
				     <GIC_SPI 849 IRQ_TYPE_LEVEL_HIGH>,
				     <GIC_SPI 802 IRQ_TYPE_LEVEL_HIGH>,
				     <GIC_SPI 803 IRQ_TYPE_LEVEL_HIGH>,
				     <GIC_SPI 804 IRQ_TYPE_LEVEL_HIGH>,
				     <GIC_SPI 805 IRQ_TYPE_LEVEL_HIGH>,
				     <GIC_SPI 806 IRQ_TYPE_LEVEL_HIGH>,
				     <GIC_SPI 807 IRQ_TYPE_LEVEL_HIGH>,
				     <GIC_SPI 808 IRQ_TYPE_LEVEL_HIGH>,
				     <GIC_SPI 809 IRQ_TYPE_LEVEL_HIGH>,
				     <GIC_SPI 810 IRQ_TYPE_LEVEL_HIGH>,
				     <GIC_SPI 811 IRQ_TYPE_LEVEL_HIGH>,
				     <GIC_SPI 812 IRQ_TYPE_LEVEL_HIGH>,
				     <GIC_SPI 813 IRQ_TYPE_LEVEL_HIGH>,
				     <GIC_SPI 814 IRQ_TYPE_LEVEL_HIGH>,
				     <GIC_SPI 836 IRQ_TYPE_LEVEL_HIGH>,
				     <GIC_SPI 837 IRQ_TYPE_LEVEL_HIGH>,
				     <GIC_SPI 838 IRQ_TYPE_LEVEL_HIGH>,
				     <GIC_SPI 839 IRQ_TYPE_LEVEL_HIGH>,
				     <GIC_SPI 854 IRQ_TYPE_LEVEL_HIGH>,
				     <GIC_SPI 855 IRQ_TYPE_LEVEL_HIGH>,
				     <GIC_SPI 856 IRQ_TYPE_LEVEL_HIGH>,
				     <GIC_SPI 790 IRQ_TYPE_LEVEL_HIGH>,
				     <GIC_SPI 791 IRQ_TYPE_LEVEL_HIGH>,
				     <GIC_SPI 792 IRQ_TYPE_LEVEL_HIGH>,
				     <GIC_SPI 793 IRQ_TYPE_LEVEL_HIGH>,
				     <GIC_SPI 794 IRQ_TYPE_LEVEL_HIGH>,
				     <GIC_SPI 795 IRQ_TYPE_LEVEL_HIGH>,
				     <GIC_SPI 796 IRQ_TYPE_LEVEL_HIGH>,
				     <GIC_SPI 639 IRQ_TYPE_LEVEL_HIGH>,
				     <GIC_SPI 79 IRQ_TYPE_LEVEL_HIGH>,
				     <GIC_SPI 640 IRQ_TYPE_LEVEL_HIGH>;
		};

		intc: interrupt-controller@17a00000 {
			compatible = "arm,gic-v3";
			reg = <0x0 0x17a00000 0x0 0x10000>,	/* GICD */
			      <0x0 0x17a60000 0x0 0x100000>;	/* GICR * 8 */
			interrupt-controller;
			#interrupt-cells = <3>;
			interrupts = <GIC_PPI 9 IRQ_TYPE_LEVEL_HIGH>;
			#redistributor-regions = <1>;
			redistributor-stride = <0x0 0x20000>;
		};

		memtimer: timer@17c20000 {
			compatible = "arm,armv7-timer-mem";
			reg = <0x0 0x17c20000 0x0 0x1000>;
			ranges = <0x0 0x0 0x0 0x20000000>;
			#address-cells = <1>;
			#size-cells = <1>;

			frame@17c21000 {
				reg = <0x17c21000 0x1000>,
				      <0x17c22000 0x1000>;
				interrupts = <GIC_SPI 8 IRQ_TYPE_LEVEL_HIGH>,
					     <GIC_SPI 6 IRQ_TYPE_LEVEL_HIGH>;
				frame-number = <0>;
			};

			frame@17c23000 {
				reg = <0x17c23000 0x1000>;
				interrupts = <GIC_SPI 9 IRQ_TYPE_LEVEL_HIGH>;
				frame-number = <1>;
				status = "disabled";
			};

			frame@17c25000 {
				reg = <0x17c25000 0x1000>;
				interrupts = <GIC_SPI 10 IRQ_TYPE_LEVEL_HIGH>;
				frame-number = <2>;
				status = "disabled";
			};

			frame@17c27000 {
				reg = <0x17c27000 0x1000>;
				interrupts = <GIC_SPI 11 IRQ_TYPE_LEVEL_HIGH>;
				frame-number = <3>;
				status = "disabled";
			};

			frame@17c29000 {
				reg = <0x17c29000 0x1000>;
				interrupts = <GIC_SPI 12 IRQ_TYPE_LEVEL_HIGH>;
				frame-number = <4>;
				status = "disabled";
			};

			frame@17c2b000 {
				reg = <0x17c2b000 0x1000>;
				interrupts = <GIC_SPI 13 IRQ_TYPE_LEVEL_HIGH>;
				frame-number = <5>;
				status = "disabled";
			};

			frame@17c2d000 {
				reg = <0x17c2d000 0x1000>;
				interrupts = <GIC_SPI 14 IRQ_TYPE_LEVEL_HIGH>;
				frame-number = <6>;
				status = "disabled";
			};
		};

		watchdog@17c10000 {
			compatible = "qcom,apss-wdt-sa7255p", "qcom,kpss-wdt";
			reg = <0x0 0x17c10000 0x0 0x1000>;
			clocks = <&sleep_clk>;
			interrupts = <GIC_SPI 0 IRQ_TYPE_EDGE_RISING>;
		};

		cpufreq_hw: cpufreq-hw@18591000 {
			compatible = "qcom,cpufreq-epss",
				     "qcom,qcs8300-cpufreq-epss";
			reg = <0x0 0x18591000 0x0 0x1000>,
			      <0x0 0x18594000 0x0 0x1000>,
			      <0x0 0x18593000 0x0 0x1000>;
			reg-names = "freq-domain0", "freq-domain1", "freq-domain2";
			interrupts = <GIC_SPI 31 IRQ_TYPE_LEVEL_HIGH>,
				     <GIC_SPI 86 IRQ_TYPE_LEVEL_HIGH>,
				     <GIC_SPI 32 IRQ_TYPE_LEVEL_HIGH>;
			interrupt-names = "dcvsh-irq-0", "dcvsh-irq-1", "dcvsh-irq-2";

			clocks = <&bi_tcxo_div2>, <&gpll0_board_clk>;
			clock-names = "xo", "alternate";

			#freq-domain-cells = <1>;
		};

		pcie0: pci@400000000 {
			compatible = "qcom,pcie-ecam-rc";
			reg = <0x4 0x00000000 0x0 0x10000000>;

			device_type = "pci";

			#address-cells = <3>;
			#size-cells = <2>;

			ranges = <0x01000000 0x0 0x40000000 0x0 0x40000000 0x0 0x100000>,
				 <0x02000000 0x0 0x40100000 0x0 0x40100000 0x0 0x1ff00000>,
				 <0x43000000 0x4 0x10100000 0x4 0x10100000 0x0 0x100000>;
			bus-range = <0x00 0xff>;

			dma-coherent;

			linux,pci-domain = <0>;

			interrupts = <GIC_SPI 307 IRQ_TYPE_LEVEL_HIGH>,
				     <GIC_SPI 308 IRQ_TYPE_LEVEL_HIGH>,
				     <GIC_SPI 309 IRQ_TYPE_LEVEL_HIGH>,
				     <GIC_SPI 312 IRQ_TYPE_LEVEL_HIGH>,
				     <GIC_SPI 313 IRQ_TYPE_LEVEL_HIGH>,
				     <GIC_SPI 314 IRQ_TYPE_LEVEL_HIGH>,
				     <GIC_SPI 374 IRQ_TYPE_LEVEL_HIGH>,
				     <GIC_SPI 375 IRQ_TYPE_LEVEL_HIGH>;
			interrupt-parent = <&intc>;

			iommus = <&pcie_smmu 0x00 0x7f>;
			iommu-map = <0x0 &pcie_smmu 0x0000 0x1>,
				    <0x100 &pcie_smmu 0x0001 0x1>,
				    <0x200 &pcie_smmu 0x0002 0x1>,
				    <0x300 &pcie_smmu 0x0003 0x1>;

			status = "disabled";
		};

		pcie1: pci@600000000 {
			compatible = "qcom,pcie-ecam-rc";
			reg = <0x6 0x00000000 0x0 0x10000000>;

			device_type = "pci";

			#address-cells = <3>;
			#size-cells = <2>;

			ranges = <0x01000000 0x0 0x60000000 0x0 0x60000000 0x0 0x100000>,
				 <0x02000000 0x0 0x60100000 0x0 0x60100000 0x0 0x1ff00000>,
				 <0x43000000 0x6 0x10100000 0x6 0x10100000 0x0 0x100000>;
			bus-range = <0x00 0xff>;

			dma-coherent;

			linux,pci-domain = <1>;

			interrupts = <GIC_SPI 519 IRQ_TYPE_LEVEL_HIGH>,
				     <GIC_SPI 140 IRQ_TYPE_LEVEL_HIGH>,
				     <GIC_SPI 141 IRQ_TYPE_LEVEL_HIGH>,
				     <GIC_SPI 142 IRQ_TYPE_LEVEL_HIGH>,
				     <GIC_SPI 143 IRQ_TYPE_LEVEL_HIGH>,
				     <GIC_SPI 144 IRQ_TYPE_LEVEL_HIGH>,
				     <GIC_SPI 145 IRQ_TYPE_LEVEL_HIGH>,
				     <GIC_SPI 146 IRQ_TYPE_LEVEL_HIGH>;
			interrupt-parent = <&intc>;

			iommus = <&pcie_smmu 0x80 0x7f>;
			iommu-map = <0x0 &pcie_smmu 0x0080 0x1>,
				    <0x100 &pcie_smmu 0x0081 0x1>,
				    <0x200 &pcie_smmu 0x0082 0x1>,
				    <0x208 &pcie_smmu 0x0083 0x1>,
				    <0x210 &pcie_smmu 0x0084 0x1>,
				    <0x300 &pcie_smmu 0x0085 0x1>,
				    <0xab00 &pcie_smmu 0x0086 0x1>;

			status = "disabled";
		};
	};

	thermal-zones {
		aoss-0-thermal {
			thermal-sensors = <&tsens0 0>;

			trips {
				trip-point0 {
					temperature = <105000>;
					hysteresis = <10000>;
					type = "passive";
				};

				trip-point1 {
					temperature = <115000>;
					hysteresis = <10000>;
					type = "passive";
				};
			};
		};

		cpu-0-0-0-thermal {
			polling-delay-passive = <10>;

			thermal-sensors = <&tsens0 1>;

			trips {
				trip-point0 {
					temperature = <105000>;
					hysteresis = <10000>;
					type = "passive";
				};

				trip-point1 {
					temperature = <115000>;
					hysteresis = <10000>;
					type = "passive";
				};
			};
		};

		cpu-0-1-0-thermal {
			polling-delay-passive = <10>;

			thermal-sensors = <&tsens0 2>;

			trips {
				trip-point0 {
					temperature = <105000>;
					hysteresis = <10000>;
					type = "passive";
				};

				trip-point1 {
					temperature = <115000>;
					hysteresis = <10000>;
					type = "passive";
				};
			};
		};

		cpu-0-2-0-thermal {
			polling-delay-passive = <10>;

			thermal-sensors = <&tsens0 3>;

			trips {
				trip-point0 {
					temperature = <105000>;
					hysteresis = <10000>;
					type = "passive";
				};

				trip-point1 {
					temperature = <115000>;
					hysteresis = <10000>;
					type = "passive";
				};
			};
		};

		cpu-0-3-0-thermal {
			polling-delay-passive = <10>;

			thermal-sensors = <&tsens0 4>;

			trips {
				trip-point0 {
					temperature = <105000>;
					hysteresis = <10000>;
					type = "passive";
				};

				trip-point1 {
					temperature = <115000>;
					hysteresis = <10000>;
					type = "passive";
				};
			};
		};

		gpuss-0-thermal {
			polling-delay-passive = <10>;

			thermal-sensors = <&tsens0 5>;

			trips {
				trip-point0 {
					temperature = <105000>;
					hysteresis = <10000>;
					type = "passive";
				};

				trip-point1 {
					temperature = <115000>;
					hysteresis = <10000>;
					type = "passive";
				};
			};
		};

		audio-thermal {
			thermal-sensors = <&tsens0 6>;

			trips {
				trip-point0 {
					temperature = <105000>;
					hysteresis = <10000>;
					type = "passive";
				};

				trip-point1 {
					temperature = <115000>;
					hysteresis = <10000>;
					type = "passive";
				};
			};
		};

		camss-0-thermal {
			thermal-sensors = <&tsens0 7>;

			trips {
				trip-point0 {
					temperature = <105000>;
					hysteresis = <10000>;
					type = "passive";
				};

				trip-point1 {
					temperature = <115000>;
					hysteresis = <10000>;
					type = "passive";
				};
			};
		};

		pcie-0-thermal {
			thermal-sensors = <&tsens0 8>;

			trips {
				trip-point0 {
					temperature = <105000>;
					hysteresis = <10000>;
					type = "passive";
				};

				trip-point1 {
					temperature = <115000>;
					hysteresis = <10000>;
					type = "passive";
				};
			};
		};

		cpuss-0-0-thermal {
			thermal-sensors = <&tsens0 9>;

			trips {
				trip-point0 {
					temperature = <105000>;
					hysteresis = <10000>;
					type = "passive";
				};

				trip-point1 {
					temperature = <115000>;
					hysteresis = <10000>;
					type = "passive";
				};
			};
		};

		aoss-1-thermal {
			thermal-sensors = <&tsens1 0>;

			trips {
				trip-point0 {
					temperature = <105000>;
					hysteresis = <10000>;
					type = "passive";
				};

				trip-point1 {
					temperature = <115000>;
					hysteresis = <10000>;
					type = "passive";
				};
			};
		};

		cpu-0-0-1-thermal {
			polling-delay-passive = <10>;

			thermal-sensors = <&tsens1 1>;

			trips {
				trip-point0 {
					temperature = <105000>;
					hysteresis = <10000>;
					type = "passive";
				};

				trip-point1 {
					temperature = <115000>;
					hysteresis = <10000>;
					type = "passive";
				};
			};
		};

		cpu-0-1-1-thermal {
			polling-delay-passive = <10>;

			thermal-sensors = <&tsens1 2>;

			trips {
				trip-point0 {
					temperature = <105000>;
					hysteresis = <10000>;
					type = "passive";
				};

				trip-point1 {
					temperature = <115000>;
					hysteresis = <10000>;
					type = "passive";
				};
			};
		};

		cpu-0-2-1-thermal {
			polling-delay-passive = <10>;

			thermal-sensors = <&tsens1 3>;

			trips {
				trip-point0 {
					temperature = <105000>;
					hysteresis = <10000>;
					type = "passive";
				};

				trip-point1 {
					temperature = <115000>;
					hysteresis = <10000>;
					type = "passive";
				};
			};
		};

		cpu-0-3-1-thermal {
			polling-delay-passive = <10>;

			thermal-sensors = <&tsens1 4>;

			trips {
				trip-point0 {
					temperature = <105000>;
					hysteresis = <10000>;
					type = "passive";
				};

				trip-point1 {
					temperature = <115000>;
					hysteresis = <10000>;
					type = "passive";
				};
			};
		};

		gpuss-1-thermal {
			polling-delay-passive = <10>;

			thermal-sensors = <&tsens1 5>;

			trips {
				trip-point0 {
					temperature = <105000>;
					hysteresis = <10000>;
					type = "passive";
				};

				trip-point1 {
					temperature = <115000>;
					hysteresis = <10000>;
					type = "passive";
				};
			};
		};

		video-thermal {
			thermal-sensors = <&tsens1 6>;

			trips {
				trip-point0 {
					temperature = <105000>;
					hysteresis = <10000>;
					type = "passive";
				};

				trip-point1 {
					temperature = <115000>;
					hysteresis = <10000>;
					type = "passive";
				};
			};
		};

		camss-1-thermal {
			thermal-sensors = <&tsens1 7>;

			trips {
				trip-point0 {
					temperature = <105000>;
					hysteresis = <10000>;
					type = "passive";
				};

				trip-point1 {
					temperature = <115000>;
					hysteresis = <10000>;
					type = "passive";
				};
			};
		};

		pcie-1-thermal {
			thermal-sensors = <&tsens1 8>;

			trips {
				trip-point0 {
					temperature = <105000>;
					hysteresis = <10000>;
					type = "passive";
				};

				trip-point1 {
					temperature = <115000>;
					hysteresis = <10000>;
					type = "passive";
				};
			};
		};

		cpuss-0-1-thermal {
			thermal-sensors = <&tsens1 9>;

			trips {
				trip-point0 {
					temperature = <105000>;
					hysteresis = <10000>;
					type = "passive";
				};

				trip-point1 {
					temperature = <115000>;
					hysteresis = <10000>;
					type = "passive";
				};
			};
		};

		aoss-2-thermal {
			thermal-sensors = <&tsens2 0>;

			trips {
				trip-point0 {
					temperature = <105000>;
					hysteresis = <10000>;
					type = "passive";
				};

				trip-point1 {
					temperature = <115000>;
					hysteresis = <10000>;
					type = "passive";
				};
			};
		};

		cpu-1-0-0-thermal {
			polling-delay-passive = <10>;

			thermal-sensors = <&tsens2 1>;

			trips {
				trip-point0 {
					temperature = <105000>;
					hysteresis = <10000>;
					type = "passive";
				};

				trip-point1 {
					temperature = <115000>;
					hysteresis = <10000>;
					type = "passive";
				};
			};
		};

		cpu-1-1-0-thermal {
			polling-delay-passive = <10>;

			thermal-sensors = <&tsens2 2>;

			trips {
				trip-point0 {
					temperature = <105000>;
					hysteresis = <10000>;
					type = "passive";
				};

				trip-point1 {
					temperature = <115000>;
					hysteresis = <10000>;
					type = "passive";
				};
			};
		};

		cpu-1-2-0-thermal {
			polling-delay-passive = <10>;

			thermal-sensors = <&tsens2 3>;

			trips {
				trip-point0 {
					temperature = <105000>;
					hysteresis = <10000>;
					type = "passive";
				};

				trip-point1 {
					temperature = <115000>;
					hysteresis = <10000>;
					type = "passive";
				};
			};
		};

		cpu-1-3-0-thermal {
			polling-delay-passive = <10>;

			thermal-sensors = <&tsens2 4>;

			trips {
				trip-point0 {
					temperature = <105000>;
					hysteresis = <10000>;
					type = "passive";
				};

				trip-point1 {
					temperature = <115000>;
					hysteresis = <10000>;
					type = "passive";
				};
			};
		};

		nsp-0-0-0-thermal {
			polling-delay-passive = <10>;

			thermal-sensors = <&tsens2 5>;

			trips {
				trip-point0 {
					temperature = <105000>;
					hysteresis = <10000>;
					type = "passive";
				};

				trip-point1 {
					temperature = <115000>;
					hysteresis = <10000>;
					type = "passive";
				};
			};
		};

		nsp-0-1-0-thermal {
			polling-delay-passive = <10>;

			thermal-sensors = <&tsens2 6>;

			trips {
				trip-point0 {
					temperature = <105000>;
					hysteresis = <10000>;
					type = "passive";
				};

				trip-point1 {
					temperature = <115000>;
					hysteresis = <10000>;
					type = "passive";
				};
			};
		};

		nsp-0-2-0-thermal {
			polling-delay-passive = <10>;

			thermal-sensors = <&tsens2 7>;

			trips {
				trip-point0 {
					temperature = <105000>;
					hysteresis = <10000>;
					type = "passive";
				};

				trip-point1 {
					temperature = <115000>;
					hysteresis = <10000>;
					type = "passive";
				};
			};
		};

		ddrss-0-thermal {
			thermal-sensors = <&tsens2 8>;

			trips {
				trip-point0 {
					temperature = <105000>;
					hysteresis = <10000>;
					type = "passive";
				};

				trip-point1 {
					temperature = <115000>;
					hysteresis = <10000>;
					type = "passive";
				};
			};
		};

		cpuss-1-0-thermal {
			thermal-sensors = <&tsens2 9>;

			trips {
				trip-point0 {
					temperature = <105000>;
					hysteresis = <10000>;
					type = "passive";
				};

				trip-point1 {
					temperature = <115000>;
					hysteresis = <10000>;
					type = "passive";
				};
			};
		};

		aoss-3-thermal {
			thermal-sensors = <&tsens3 0>;

			trips {
				trip-point0 {
					temperature = <105000>;
					hysteresis = <10000>;
					type = "passive";
				};

				trip-point1 {
					temperature = <115000>;
					hysteresis = <10000>;
					type = "passive";
				};
			};
		};

		cpu-1-0-1-thermal {
			polling-delay-passive = <10>;

			thermal-sensors = <&tsens3 1>;

			trips {
				trip-point0 {
					temperature = <105000>;
					hysteresis = <10000>;
					type = "passive";
				};

				trip-point1 {
					temperature = <115000>;
					hysteresis = <10000>;
					type = "passive";
				};
			};
		};

		cpu-1-1-1-thermal {
			polling-delay-passive = <10>;

			thermal-sensors = <&tsens3 2>;

			trips {
				trip-point0 {
					temperature = <105000>;
					hysteresis = <10000>;
					type = "passive";
				};

				trip-point1 {
					temperature = <115000>;
					hysteresis = <10000>;
					type = "passive";
				};
			};
		};

		cpu-1-2-1-thermal {
			polling-delay-passive = <10>;

			thermal-sensors = <&tsens3 3>;

			trips {
				trip-point0 {
					temperature = <105000>;
					hysteresis = <10000>;
					type = "passive";
				};

				trip-point1 {
					temperature = <115000>;
					hysteresis = <10000>;
					type = "passive";
				};
			};
		};

		cpu-1-3-1-thermal {
			polling-delay-passive = <10>;

			thermal-sensors = <&tsens3 4>;

			trips {
				trip-point0 {
					temperature = <105000>;
					hysteresis = <10000>;
					type = "passive";
				};

				trip-point1 {
					temperature = <115000>;
					hysteresis = <10000>;
					type = "passive";
				};
			};
		};

		nsp-0-0-1-thermal {
			polling-delay-passive = <10>;

			thermal-sensors = <&tsens3 5>;

			trips {
				trip-point0 {
					temperature = <105000>;
					hysteresis = <10000>;
					type = "passive";
				};

				trip-point1 {
					temperature = <115000>;
					hysteresis = <10000>;
					type = "passive";
				};
			};
		};

		nsp-0-1-1-thermal {
			polling-delay-passive = <10>;

			thermal-sensors = <&tsens3 6>;

			trips {
				trip-point0 {
					temperature = <105000>;
					hysteresis = <10000>;
					type = "passive";
				};

				trip-point1 {
					temperature = <115000>;
					hysteresis = <10000>;
					type = "passive";
				};
			};
		};

		nsp-0-2-1-thermal {
			polling-delay-passive = <10>;

			thermal-sensors = <&tsens3 7>;

			trips {
				trip-point0 {
					temperature = <105000>;
					hysteresis = <10000>;
					type = "passive";
				};

				trip-point1 {
					temperature = <115000>;
					hysteresis = <10000>;
					type = "passive";
				};
			};
		};

		ddrss-1-thermal {
			thermal-sensors = <&tsens3 8>;

			trips {
				trip-point0 {
					temperature = <105000>;
					hysteresis = <10000>;
					type = "passive";
				};

				trip-point1 {
					temperature = <115000>;
					hysteresis = <10000>;
					type = "passive";
				};
			};
		};

		cpuss-1-1-thermal {
			thermal-sensors = <&tsens3 9>;

			trips {
				trip-point0 {
					temperature = <105000>;
					hysteresis = <10000>;
					type = "passive";
				};

				trip-point1 {
					temperature = <115000>;
					hysteresis = <10000>;
					type = "passive";
				};
			};
		};
	};

	arch_timer: timer {
		compatible = "arm,armv8-timer";
		interrupts = <GIC_PPI 13 (GIC_CPU_MASK_SIMPLE(8) | IRQ_TYPE_LEVEL_LOW)>,
			     <GIC_PPI 14 (GIC_CPU_MASK_SIMPLE(8) | IRQ_TYPE_LEVEL_LOW)>,
			     <GIC_PPI 11 (GIC_CPU_MASK_SIMPLE(8) | IRQ_TYPE_LEVEL_LOW)>,
			     <GIC_PPI 12 (GIC_CPU_MASK_SIMPLE(8) | IRQ_TYPE_LEVEL_LOW)>;
		clock-frequency = <19200000>;
	};
};
